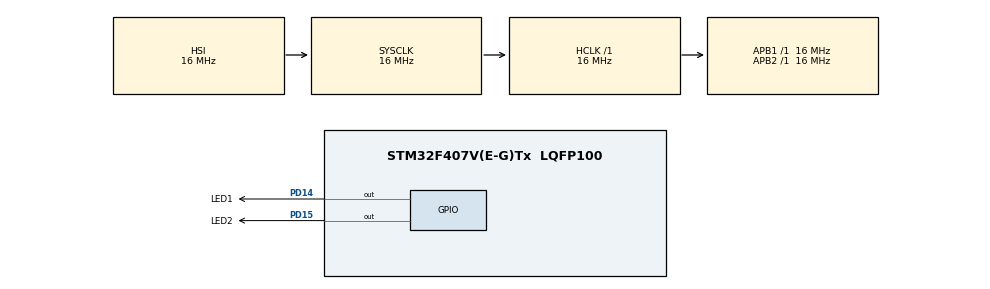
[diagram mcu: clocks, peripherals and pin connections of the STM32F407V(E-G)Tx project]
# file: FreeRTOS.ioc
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FREERTOS.Tasks01=defaultTask,0,128,StartDefaultTask,Default,NULL,Dynamic,NULL,NULL;Led1,0,128,task_led1,Default,NULL,Dynamic,NULL,NULL;led2,0,128,task_led2,Default,NULL,Dynamic,NULL,NULL
FREERTOS.configUSE_NEWLIB_REENTRANT=1
Mcu.Family=STM32F4
Mcu.Name=STM32F407V(E-G)Tx
Mcu.Package=LQFP100
NVIC.PriorityGroup=NVIC_PRIORITYGROUP_4
NVIC.TIM6_DAC_IRQn=true\:15\:0\:false\:false\:true\:false\:false\:true\:true
NVIC.TimeBase=TIM6_DAC_IRQn
NVIC.TimeBaseIP=TIM6
PD14.GPIO_Label=LED1
PD14.Signal=GPIO_Output
PD15.GPIO_Label=LED2
PD15.Signal=GPIO_Output
ProjectManager.HeapSize=0x200
ProjectManager.StackSize=0x400
ProjectManager.TargetToolchain=STM32CubeIDE
RCC.AHBFreq_Value=16000000
RCC.APB1Freq_Value=16000000
RCC.APB2Freq_Value=16000000
RCC.CortexFreq_Value=16000000
RCC.HSE_VALUE=25000000
RCC.HSI_VALUE=16000000
RCC.LSE_VALUE=32768
RCC.SYSCLKFreq_VALUE=16000000
RCC.VCOOutputFreq_Value=192000000
VP_FREERTOS_VS_CMSIS_V1.Mode=CMSIS_V1
VP_SYS_VS_tim6.Mode=TIM6
board=custom

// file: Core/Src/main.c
/* USER CODE BEGIN Header */
/**
  ******************************************************************************
  * @file           : main.c
  * @brief          : Main program body
  ******************************************************************************
  * @attention
  *
  * Copyright (c) 2023 STMicroelectronics.
  * All rights reserved.
  *
  * This software is licensed under terms that can be found in the LICENSE file
  * in the root directory of this software component.
  * If no LICENSE file comes with this software, it is provided AS-IS.
  *
  ******************************************************************************
  */
/* USER CODE END Header */
#include "main.h"
#include "cmsis_os.h"
#include "gpio.h"

void SystemClock_Config(void);
void MX_FREERTOS_Init(void);

int main(void)
{

  /* MCU Configuration--------------------------------------------------------*/

  /* Reset of all peripherals, Initializes the Flash interface and the Systick. */
  HAL_Init();

  /* Configure the system clock */
  SystemClock_Config();

  /* Initialize all configured peripherals */
  MX_GPIO_Init();

  /* Call init function for freertos objects (in freertos.c) */
  MX_FREERTOS_Init();

  /* Start scheduler */
  osKernelStart();
  /* We should never get here as control is now taken by the scheduler */
  /* Infinite loop */
  while (1)
  {

  }
}

void SystemClock_Config(void)
{
  RCC_OscInitTypeDef RCC_OscInitStruct = {0};
  RCC_ClkInitTypeDef RCC_ClkInitStruct = {0};

  /** Configure the main internal regulator output voltage
  */
  __HAL_RCC_PWR_CLK_ENABLE();
  __HAL_PWR_VOLTAGESCALING_CONFIG(PWR_REGULATOR_VOLTAGE_SCALE1);

  /** Initializes the RCC Oscillators according to the specified parameters
  * in the RCC_OscInitTypeDef structure.
  */
  RCC_OscInitStruct.OscillatorType = RCC_OSCILLATORTYPE_HSI;
  RCC_OscInitStruct.HSIState = RCC_HSI_ON;
  RCC_OscInitStruct.HSICalibrationValue = RCC_HSICALIBRATION_DEFAULT;
  RCC_OscInitStruct.PLL.PLLState = RCC_PLL_NONE;
  if (HAL_RCC_OscConfig(&RCC_OscInitStruct) != HAL_OK)
  {
    Error_Handler();
  }

  /** Initializes the CPU, AHB and APB buses clocks
  */
  RCC_ClkInitStruct.ClockType = RCC_CLOCKTYPE_HCLK|RCC_CLOCKTYPE_SYSCLK
                              |RCC_CLOCKTYPE_PCLK1|RCC_CLOCKTYPE_PCLK2;
  RCC_ClkInitStruct.SYSCLKSource = RCC_SYSCLKSOURCE_HSI;
  RCC_ClkInitStruct.AHBCLKDivider = RCC_SYSCLK_DIV1;
  RCC_ClkInitStruct.APB1CLKDivider = RCC_HCLK_DIV1;
  RCC_ClkInitStruct.APB2CLKDivider = RCC_HCLK_DIV1;

  if (HAL_RCC_ClockConfig(&RCC_ClkInitStruct, FLASH_LATENCY_0) != HAL_OK)
  {
    Error_Handler();
  }
}

void HAL_TIM_PeriodElapsedCallback(TIM_HandleTypeDef *htim)
{
  if (htim->Instance == TIM6) {
    HAL_IncTick();
  }
}

void Error_Handler(void)
{
  __disable_irq();
  while (1)
  {
  }
}

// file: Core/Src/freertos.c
/* USER CODE BEGIN Header */
/**
  ******************************************************************************
  * File Name          : freertos.c
  * Description        : Code for freertos applications
  ******************************************************************************
  * @attention
  *
  * Copyright (c) 2023 STMicroelectronics.
  * All rights reserved.
  *
  * This software is licensed under terms that can be found in the LICENSE file
  * in the root directory of this software component.
  * If no LICENSE file comes with this software, it is provided AS-IS.
  *
  ******************************************************************************
  */
/* USER CODE END Header */

#include "FreeRTOS.h"
#include "task.h"
#include "main.h"
#include "cmsis_os.h"

/* USER CODE BEGIN Includes */
#include "stdio.h"
/* USER CODE END Includes */

osThreadId defaultTaskHandle;
osThreadId Led1Handle;
osThreadId led2Handle;

void StartDefaultTask(void const * argument);
void task_led1(void const * argument);
void task_led2(void const * argument);

void MX_FREERTOS_Init(void); /* (MISRA C 2004 rule 8.1) */

/* GetIdleTaskMemory prototype (linked to static allocation support) */
void vApplicationGetIdleTaskMemory( StaticTask_t **ppxIdleTaskTCBBuffer, StackType_t **ppxIdleTaskStackBuffer, uint32_t *pulIdleTaskStackSize );

/* USER CODE BEGIN GET_IDLE_TASK_MEMORY */
static StaticTask_t xIdleTaskTCBBuffer;
static StackType_t xIdleStack[configMINIMAL_STACK_SIZE];

void vApplicationGetIdleTaskMemory( StaticTask_t **ppxIdleTaskTCBBuffer, StackType_t **ppxIdleTaskStackBuffer, uint32_t *pulIdleTaskStackSize )
{
  *ppxIdleTaskTCBBuffer = &xIdleTaskTCBBuffer;
  *ppxIdleTaskStackBuffer = &xIdleStack[0];
  *pulIdleTaskStackSize = configMINIMAL_STACK_SIZE;
  /* place for user code */
}
/* USER CODE END GET_IDLE_TASK_MEMORY */

void MX_FREERTOS_Init(void) {

  /* Create the thread(s) */
  /* definition and creation of defaultTask */
  osThreadDef(defaultTask, StartDefaultTask, osPriorityNormal, 0, 128);
  defaultTaskHandle = osThreadCreate(osThread(defaultTask), NULL);

  /* definition and creation of Led1 */
  osThreadDef(Led1, task_led1, osPriorityNormal, 0, 128);
  Led1Handle = osThreadCreate(osThread(Led1), NULL);

  /* definition and creation of led2 */
  osThreadDef(led2, task_led2, osPriorityNormal, 0, 128);
  led2Handle = osThreadCreate(osThread(led2), NULL);

}

void StartDefaultTask(void const * argument)
{
  for(;;)
  {
    osDelay(1);
  }
}

void task_led1(void const * argument)
{
  /* USER CODE BEGIN task_led1 */
  /* Infinite loop */
  for(;;)
  {
	  printf("1->[tarea 1 running]\r\n");
	  HAL_GPIO_TogglePin(LED1_GPIO_Port, LED1_Pin);
    osDelay(100);
  }
  /* USER CODE END task_led1 */
}

void task_led2(void const * argument)
{
  /* USER CODE BEGIN task_led2 */
  /* Infinite loop */
  for(;;)
  {
	  HAL_GPIO_TogglePin(LED2_GPIO_Port, LED2_Pin);
	  printf("2->[tarea 2 running]\r\n");
    osDelay(100);
  }
  /* USER CODE END task_led2 */
}

/* USER CODE BEGIN Application */
int __io_putchar(int ch){
	ITM_SendChar(ch);
	return ch;
}
/* USER CODE END Application */
